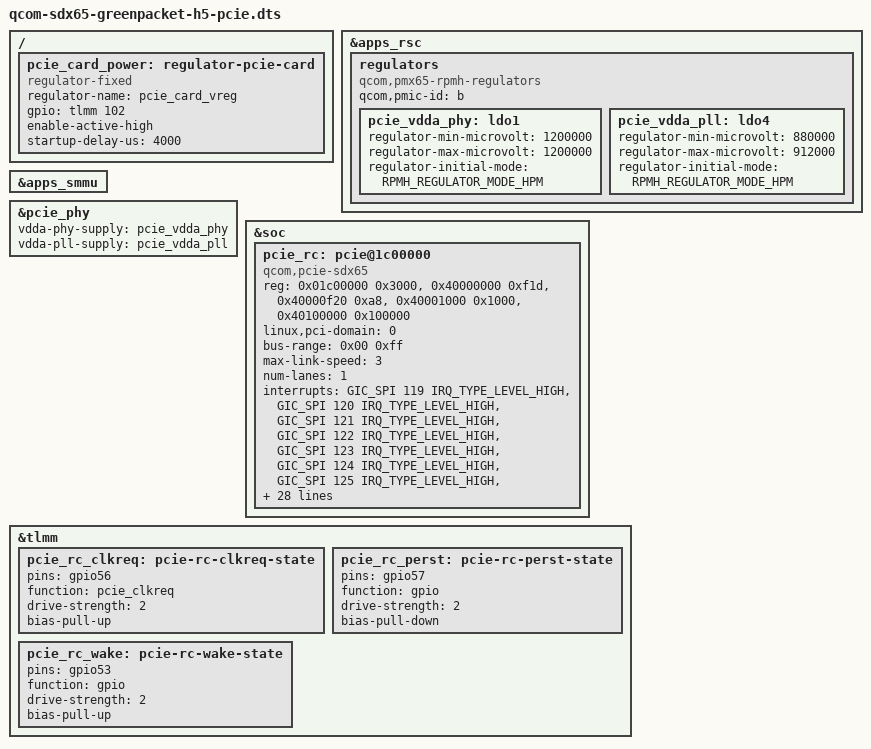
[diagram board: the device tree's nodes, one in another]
// SPDX-License-Identifier: BSD-3-Clause
/* Experimental PCIe RC bring-up. No modem or flash support is enabled. */
#include "qcom-sdx65-greenpacket-h5.dts"
#include <dt-bindings/gpio/gpio.h>
#include <dt-bindings/regulator/qcom,rpmh-regulator.h>

/ {
	pcie_card_power: regulator-pcie-card {
		compatible = "regulator-fixed";
		regulator-name = "pcie_card_vreg";
		gpio = <&tlmm 102 GPIO_ACTIVE_HIGH>;
		enable-active-high;
		startup-delay-us = <4000>;
		/* Stock DT does not specify this rail's voltage. */
	};
};

&apps_rsc {
	regulators {
		compatible = "qcom,pmx65-rpmh-regulators";
		qcom,pmic-id = "b";

		pcie_vdda_phy: ldo1 {
			regulator-min-microvolt = <1200000>;
			regulator-max-microvolt = <1200000>;
			regulator-initial-mode = <RPMH_REGULATOR_MODE_HPM>;
		};

		pcie_vdda_pll: ldo4 {
			regulator-min-microvolt = <880000>;
			regulator-max-microvolt = <912000>;
			regulator-initial-mode = <RPMH_REGULATOR_MODE_HPM>;
		};
	};
};

&apps_smmu {
	status = "okay";
};

&pcie_phy {
	vdda-phy-supply = <&pcie_vdda_phy>;
	vdda-pll-supply = <&pcie_vdda_pll>;
	status = "okay";
};

&soc {
	pcie_rc: pcie@1c00000 {
		compatible = "qcom,pcie-sdx65";
		reg = <0x01c00000 0x3000>,
		      <0x40000000 0xf1d>,
		      <0x40000f20 0xa8>,
		      <0x40001000 0x1000>,
		      <0x40100000 0x100000>;
		reg-names = "parf", "dbi", "elbi", "atu", "config";
		device_type = "pci";
		linux,pci-domain = <0>;
		bus-range = <0x00 0xff>;
		max-link-speed = <3>;
		num-lanes = <1>;
		#address-cells = <3>;
		#size-cells = <2>;
		ranges = <0x01000000 0x0 0x00000000 0x40200000 0x0 0x100000>,
			 <0x02000000 0x0 0x40300000 0x40300000 0x0 0x3fd00000>;

		interrupts = <GIC_SPI 119 IRQ_TYPE_LEVEL_HIGH>,
			     <GIC_SPI 120 IRQ_TYPE_LEVEL_HIGH>,
			     <GIC_SPI 121 IRQ_TYPE_LEVEL_HIGH>,
			     <GIC_SPI 122 IRQ_TYPE_LEVEL_HIGH>,
			     <GIC_SPI 123 IRQ_TYPE_LEVEL_HIGH>,
			     <GIC_SPI 124 IRQ_TYPE_LEVEL_HIGH>,
			     <GIC_SPI 125 IRQ_TYPE_LEVEL_HIGH>,
			     <GIC_SPI 126 IRQ_TYPE_LEVEL_HIGH>;
		interrupt-names = "msi", "msi2", "msi3", "msi4",
				  "msi5", "msi6", "msi7", "msi8";
		#interrupt-cells = <1>;
		interrupt-map-mask = <0 0 0 0x7>;
		interrupt-map = <0 0 0 1 &intc 0 141 IRQ_TYPE_LEVEL_HIGH>,
				<0 0 0 2 &intc 0 142 IRQ_TYPE_LEVEL_HIGH>,
				<0 0 0 3 &intc 0 143 IRQ_TYPE_LEVEL_HIGH>,
				<0 0 0 4 &intc 0 144 IRQ_TYPE_LEVEL_HIGH>;

		clocks = <&gcc GCC_PCIE_PIPE_CLK>,
			 <&gcc GCC_PCIE_AUX_CLK>,
			 <&gcc GCC_PCIE_CFG_AHB_CLK>,
			 <&gcc GCC_PCIE_MSTR_AXI_CLK>,
			 <&gcc GCC_PCIE_SLV_AXI_CLK>,
			 <&gcc GCC_PCIE_SLV_Q2A_AXI_CLK>,
			 <&gcc GCC_PCIE_SLEEP_CLK>;
		clock-names = "pipe", "aux", "cfg", "bus_master",
			      "bus_slave", "slave_q2a", "sleep";
		resets = <&gcc GCC_PCIE_BCR>;
		reset-names = "pci";
		power-domains = <&gcc PCIE_GDSC>;
		phys = <&pcie_phy>;
		phy-names = "pciephy";
		vdda-supply = <&pcie_vdda_phy>;
		vddpe-3v3-supply = <&pcie_card_power>;
		interconnects = <&system_noc MASTER_PCIE_0 &mc_virt SLAVE_EBI1>,
			       <&mem_noc MASTER_APPSS_PROC &system_noc SLAVE_PCIE_0>;
		interconnect-names = "pcie-mem", "cpu-pcie";
		iommu-map = <0x0 &apps_smmu 0x200 0x1>,
			    <0x100 &apps_smmu 0x201 0x1>;
		perst-gpios = <&tlmm 57 GPIO_ACTIVE_LOW>;
		pinctrl-0 = <&pcie_rc_clkreq &pcie_rc_perst &pcie_rc_wake>;
		pinctrl-names = "default";
		status = "okay";
	};
};

&tlmm {
	pcie_rc_clkreq: pcie-rc-clkreq-state {
		pins = "gpio56";
		function = "pcie_clkreq";
		drive-strength = <2>;
		bias-pull-up;
	};

	pcie_rc_perst: pcie-rc-perst-state {
		pins = "gpio57";
		function = "gpio";
		drive-strength = <2>;
		bias-pull-down;
	};

	pcie_rc_wake: pcie-rc-wake-state {
		pins = "gpio53";
		function = "gpio";
		drive-strength = <2>;
		bias-pull-up;
	};
};
